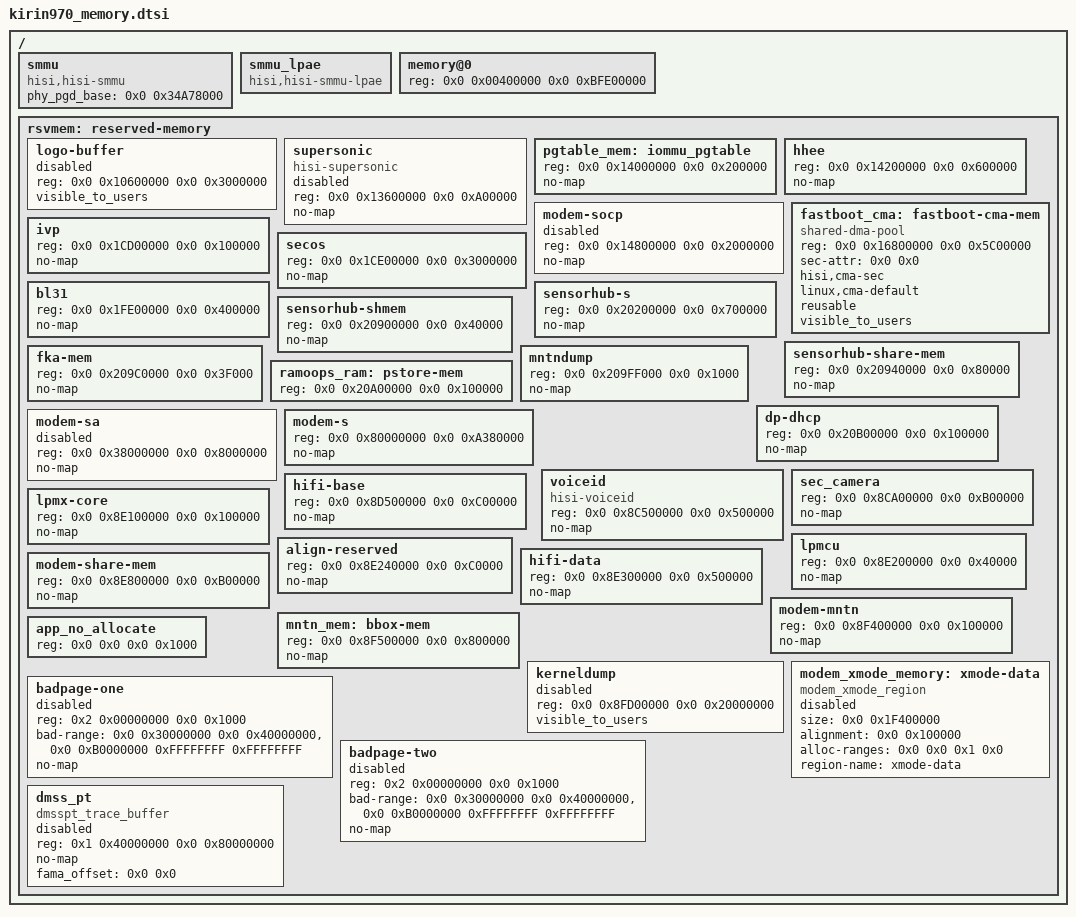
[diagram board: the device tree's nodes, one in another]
/{
	smmu {
		compatible = "hisi,hisi-smmu";
		phy_pgd_base = <0x0 0x34A78000>;
	};

	smmu_lpae{
		compatible = "hisi,hisi-smmu-lpae";
		status = "ok";
	};

	memory@0 {
		device_type = "memory";
		reg = <0x0 0x00400000 0x0 0xBFE00000>;
	};

	/* static-region */
	rsvmem:reserved-memory {
		#address-cells = <2>;
		#size-cells = <2>;
		ranges;

		logo-buffer {
			reg = <0x0 0x10600000 0x0 0x3000000>;
			status = "disabled";
			visible_to_users;
		};

		/* for supersonic */
		supersonic {
			reg = <0x0 0x13600000 0x0 0xA00000>;
			compatible = "hisi-supersonic";
			no-map;
			status = "disabled";
		};

		pgtable_mem:iommu_pgtable {
			reg = <0x0 0x14000000 0x0 0x200000>;
			no-map;
		};

		hhee {
			reg = <0x0 0x14200000 0x0 0x600000>;
			no-map;
			status = "ok";
		};

		modem-socp {
			reg = <0x0 0x14800000 0x0 0x2000000>;
			no-map;
			status = "disabled";
		};

		/*Please modify HISEE_LOG_SPACE_ADDR_MIN and HISEE_LOG_SPACE_ADDR_MAX defined in atf for hisee mntn,
		if you modify any value here!!!*/
		fastboot_cma:fastboot-cma-mem {
			reg = <0x0 0x16800000 0x0 0x5C00000>;
			compatible = "shared-dma-pool";
			sec-attr = <0x0 0x0>;
			hisi,cma-sec;
			linux,cma-default;
			reusable;
			status = "ok";
			visible_to_users;
		};

		ivp {
			reg = <0x0 0x1CD00000 0x0 0x100000>;
			no-map;
		};

		secos {
			reg = <0x0 0x1CE00000 0x0 0x3000000>;
			no-map;
		};

		bl31 {
			reg = <0x0 0x1FE00000 0x0 0x400000>;
			no-map;
		};

		sensorhub-s {
			reg = <0x0 0x20200000 0x0 0x700000>;
			no-map;
		};

		/* sensorhub share mem part1 */
		sensorhub-shmem{
			reg = <0x0 0x20900000 0x0 0x40000>;
			no-map;
		};

		/* sensorhub share mem part2 */
		sensorhub-share-mem {
			reg = <0x0 0x20940000 0x0 0x80000>;
			no-map;
		};

		/*fastboot kernel android reserve mem; non secure;no map*/
		fka-mem{
			reg = <0x0 0x209C0000 0x0 0x3F000>;
			no-map;
		};

		/* At the end of fka-mem */
		mntndump {
			reg = <0x0 0x209FF000 0x0 0x1000>;
			no-map;
		};

		ramoops_ram:pstore-mem{
			reg = <0x0 0x20A00000 0x0 0x100000>;
		};

		dp-dhcp {
			reg = <0x0 0x20B00000 0x0 0x100000>;
			no-map;
		};

		modem-sa {
			reg = <0x0 0x38000000 0x0 0x8000000>;
			no-map;
			status = "disabled";
		};

		modem-s {
			reg = <0x0 0x80000000 0x0 0xA380000>;
			no-map;
		};

		voiceid: voiceid {
			reg = <0x0 0x8C500000 0x0 0x500000>;
			compatible = "hisi-voiceid";
			no-map;
		};

		sec_camera {
			reg = <0x0 0x8CA00000 0x0 0xB00000>;
			no-map;
			status = "ok";
		};

		hifi-base {
			reg = <0x0 0x8D500000 0x0 0xC00000>;
			no-map;
		};

		lpmx-core {
			reg = <0x0 0x8E100000 0x0 0x100000>;
			no-map;
		};

		lpmcu {
			reg = <0x0 0x8E200000 0x0 0x40000>;
			no-map;
		};

		align-reserved {
			reg = <0x0 0x8E240000 0x0 0xC0000>;
			no-map;
		};

		hifi-data {
			reg = <0x0 0x8E300000 0x0 0x500000>;
			no-map;
		};

		modem-share-mem {
			reg = <0x0 0x8E800000 0x0 0xB00000>;
			no-map;
		};

		modem-mntn {
			reg = <0x0 0x8F400000 0x0 0x100000>;
			no-map;
			status = "ok";
		};

		mntn_mem:bbox-mem {
			reg = <0x0 0x8F500000 0x0 0x800000>;
			no-map;
		};

		kerneldump {
			reg = <0x0 0x8FD00000 0x0 0x20000000>;
			status = "disabled";
			visible_to_users;
		};

		app_no_allocate{
			reg = <0x0 0x0 0x0 0x1000>;
		};

		badpage-one {
			reg = <0x2 0x00000000 0x0 0x1000>;
			bad-range = <0x0 0x30000000 0x0 0x40000000>,
			            <0x0 0xB0000000 0xFFFFFFFF 0xFFFFFFFF>;
			no-map;
			status = "disabled";
		};

		badpage-two {
			reg = <0x2 0x00000000 0x0 0x1000>;
			bad-range = <0x0 0x30000000 0x0 0x40000000>,
			            <0x0 0xB0000000 0xFFFFFFFF 0xFFFFFFFF>;
			no-map;
			status = "disabled";
		};
	};

	/* dynamic-region */
	reserved-memory {
		#address-cells = <2>;
		#size-cells = <2>;
		ranges;

		modem_xmode_memory: xmode-data {
			size = <0x0 0x1F400000>;
			alignment = <0x0 0x100000>;
			alloc-ranges = <0x0 0x0 0x1 0x0>;
			compatible = "modem_xmode_region";
			region-name = "xmode-data";
			status = "disabled";
		};

		dmss_pt{
			compatible = "dmsspt_trace_buffer";
			reg = <0x1 0x40000000 0x0 0x80000000>;
			no-map;
			fama_offset = <0x0 0x0>;
			status = "disable";
		};


	};
};
